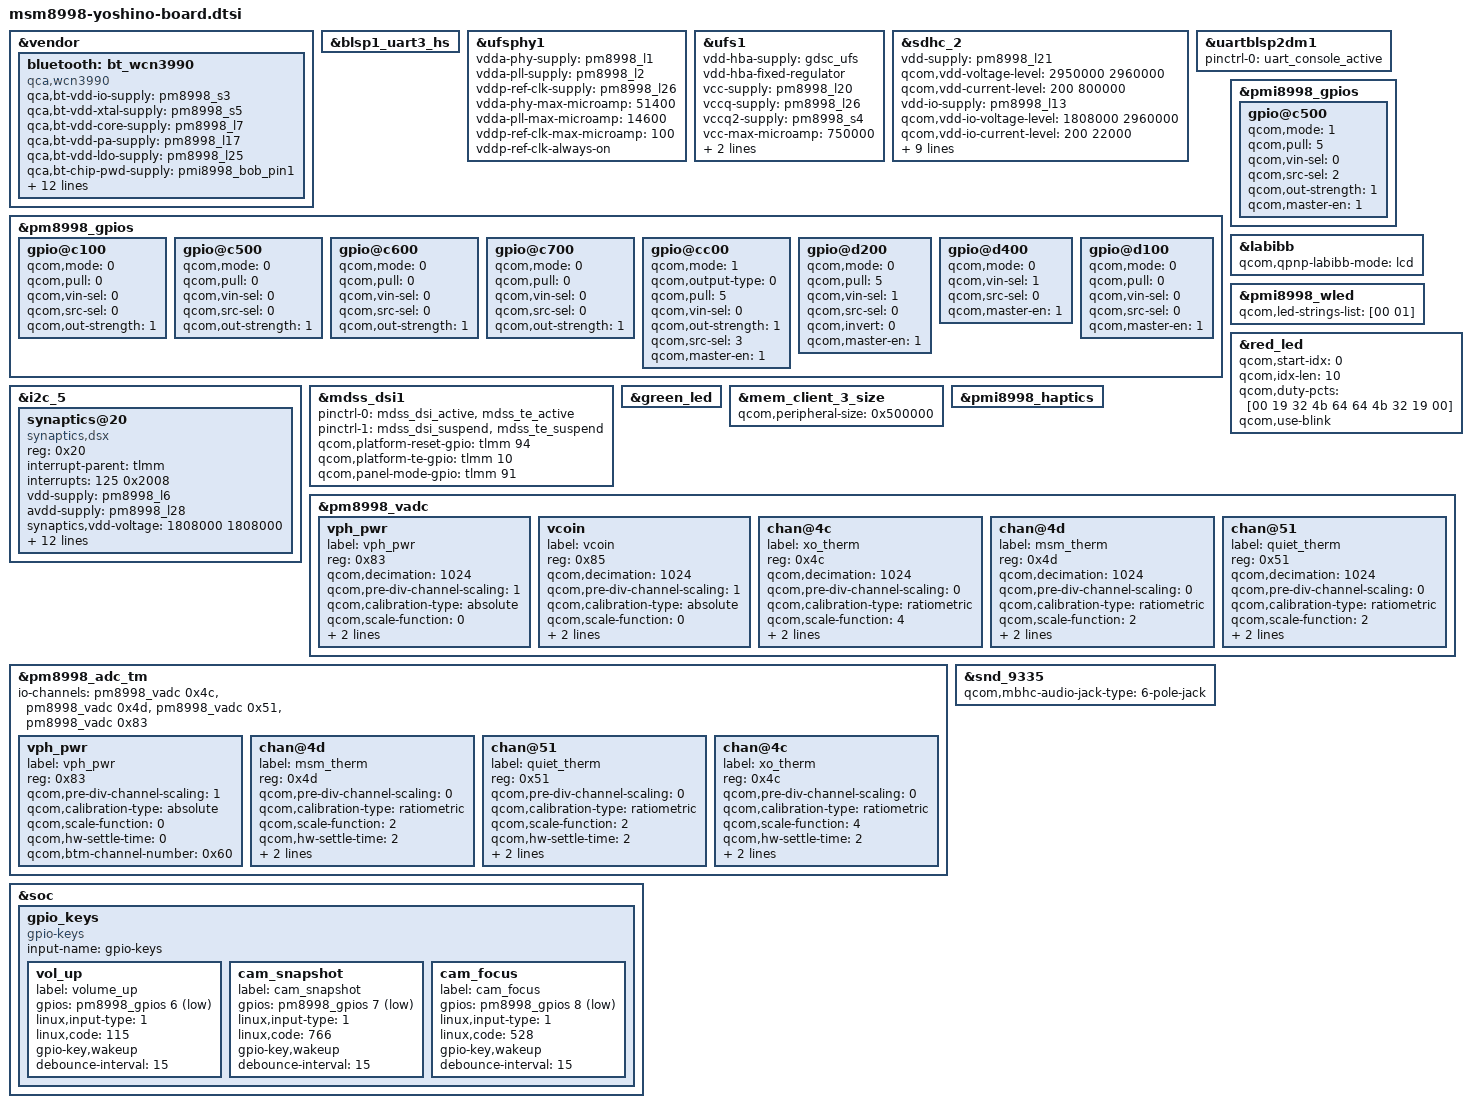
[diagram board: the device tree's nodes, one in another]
/* Copyright (c) 2016-2018, The Linux Foundation. All rights reserved.
 *
 * This program is free software; you can redistribute it and/or modify
 * it under the terms of the GNU General Public License version 2 and
 * only version 2 as published by the Free Software Foundation.
 *
 * This program is distributed in the hope that it will be useful,
 * but WITHOUT ANY WARRANTY; without even the implied warranty of
 * MERCHANTABILITY or FITNESS FOR A PARTICULAR PURPOSE.  See the
 * GNU General Public License for more details.
 */
/*
 * NOTE: This file has been modified by Sony Mobile Communications Inc.
 * Modifications are Copyright (c) 2016 Sony Mobile Communications Inc,
 * and licensed under the license of the file.
 */
/*
 * Yoshino board configuration derived from msm8998-mtp.dtsi.
 * Reference panels, DP, QTI NQ NFC and WiGig overrides are dropped
 * as they are not present on Yoshino.
 */

#include <dt-bindings/interrupt-controller/irq.h>
&vendor {
	bluetooth: bt_wcn3990 {
		compatible = "qca,wcn3990";
		qca,bt-vdd-io-supply = <&pm8998_s3>;
		qca,bt-vdd-xtal-supply = <&pm8998_s5>;
		qca,bt-vdd-core-supply = <&pm8998_l7>;
		qca,bt-vdd-pa-supply = <&pm8998_l17>;
		qca,bt-vdd-ldo-supply = <&pm8998_l25>;
		qca,bt-chip-pwd-supply = <&pmi8998_bob_pin1>;
		clocks = <&clock_rpmcc RPM_SMD_RF_CLK2_PIN>;
		clock-names = "rf_clk2";

		qca,bt-vdd-io-voltage-level = <1352000 1352000>;
		qca,bt-vdd-xtal-voltage-level = <2040000 2040000>;
		qca,bt-vdd-core-voltage-level = <1800000 1800000>;
		qca,bt-vdd-pa-voltage-level = <1304000 1304000>;
		qca,bt-vdd-ldo-voltage-level = <3312000 3312000>;
		qca,bt-chip-pwd-voltage-level = <3600000 3600000>;

		qca,bt-vdd-io-current-level = <1>; /* LPM/PFM */
		qca,bt-vdd-xtal-current-level = <1>; /* LPM/PFM */
		qca,bt-vdd-core-current-level = <1>; /* LPM/PFM */
		qca,bt-vdd-pa-current-level = <1>; /* LPM/PFM */
		qca,bt-vdd-ldo-current-level = <1>; /* LPM/PFM */
	};
};

&blsp1_uart3_hs {
	status = "ok";
};

&ufsphy1 {
	vdda-phy-supply = <&pm8998_l1>;
	vdda-pll-supply = <&pm8998_l2>;
	vddp-ref-clk-supply = <&pm8998_l26>;
	vdda-phy-max-microamp = <51400>;
	vdda-pll-max-microamp = <14600>;
	vddp-ref-clk-max-microamp = <100>;
	vddp-ref-clk-always-on;
	status = "ok";
};

&ufs1 {
	vdd-hba-supply = <&gdsc_ufs>;
	vdd-hba-fixed-regulator;
	vcc-supply = <&pm8998_l20>;
	vccq-supply = <&pm8998_l26>;
	vccq2-supply = <&pm8998_s4>;
	vcc-max-microamp = <750000>;
	vccq-max-microamp = <560000>;
	vccq2-max-microamp = <750000>;
	status = "ok";
};

&sdhc_2 {
	vdd-supply = <&pm8998_l21>;
	qcom,vdd-voltage-level = <2950000 2960000>;
	qcom,vdd-current-level = <200 800000>;

	vdd-io-supply = <&pm8998_l13>;
	qcom,vdd-io-voltage-level = <1808000 2960000>;
	qcom,vdd-io-current-level = <200 22000>;

	pinctrl-names = "active", "sleep";
	pinctrl-0 = <&sdc2_clk_on  &sdc2_cmd_on &sdc2_data_on &sdc2_cd_on>;
	pinctrl-1 = <&sdc2_clk_off &sdc2_cmd_off &sdc2_data_off &sdc2_cd_off>;

	qcom,clk-rates = <400000 20000000 25000000
				50000000 100000000 200000000>;
	qcom,bus-speed-mode = "SDR12", "SDR25", "SDR50", "DDR50", "SDR104";

	cd-gpios = <&tlmm 95 0x1>;

	status = "ok";
};

&uartblsp2dm1 {
	status = "ok";
	pinctrl-names = "default";
	pinctrl-0 = <&uart_console_active>;
};

&pm8998_gpios {
	/* GPIO 2 for Home Key */
	gpio@c100 {
		status = "okay";
		qcom,mode = <0>;
		qcom,pull = <0>;
		qcom,vin-sel = <0>;
		qcom,src-sel = <0>;
		qcom,out-strength = <1>;
	};

	/* GPIO 6 for Vol+ Key */
	gpio@c500 {
		status = "okay";
		qcom,mode = <0>;
		qcom,pull = <0>;
		qcom,vin-sel = <0>;
		qcom,src-sel = <0>;
		qcom,out-strength = <1>;
	};

	/* GPIO 7 for Snapshot Key */
	gpio@c600 {
		status = "okay";
		qcom,mode = <0>;
		qcom,pull = <0>;
		qcom,vin-sel = <0>;
		qcom,src-sel = <0>;
		qcom,out-strength = <1>;
	};

	/* GPIO 8 for Focus Key */
	gpio@c700 {
		status = "okay";
		qcom,mode = <0>;
		qcom,pull = <0>;
		qcom,vin-sel = <0>;
		qcom,src-sel = <0>;
		qcom,out-strength = <1>;
	};

	gpio@cc00 { /* GPIO 13 */
		qcom,mode = <1>;
		qcom,output-type = <0>;
		qcom,pull = <5>;
		qcom,vin-sel = <0>;
		qcom,out-strength = <1>;
		qcom,src-sel = <3>;
		qcom,master-en = <1>;
		status = "okay";
	};

	gpio@d200 { /* GPIO 19 - wil6210 refclk3_en */
		qcom,mode = <0>;		/* Input */
		qcom,pull = <5>;		/* No Pull */
		qcom,vin-sel = <1>;		/* VIN1 GPIO_MV */
		qcom,src-sel = <0>;		/* GPIO */
		qcom,invert = <0>;		/* Invert */
		qcom,master-en = <1>;		/* Enable GPIO */
		status = "okay";
	};

	/* GPIO 21 (NFC_CLK_REQ) */
	gpio@d400 {
		qcom,mode = <0>;
		qcom,vin-sel = <1>;
		qcom,src-sel = <0>;
		qcom,master-en = <1>;
		status = "okay";
	};

	/* GPIO 18 SMB138X */
	gpio@d100 {
		qcom,mode = <0>;
		qcom,pull = <0>;
		qcom,vin-sel = <0>;
		qcom,src-sel = <0>;
		qcom,master-en = <1>;
		status = "okay";
	};
};

&pmi8998_gpios {
	/* GPIO 6 for the internal QNOVO discharge FET control signal */
	gpio@c500 {
		status = "okay";
		qcom,mode = <1>;
		qcom,pull = <5>;
		qcom,vin-sel = <0>;
		qcom,src-sel = <2>;
		qcom,out-strength = <1>;
		qcom,master-en = <1>;
	};
};

&i2c_5 {
	status = "okay";
	synaptics@20 {
		compatible = "synaptics,dsx";
		reg = <0x20>;
		interrupt-parent = <&tlmm>;
		interrupts = <125 0x2008>;
		vdd-supply = <&pm8998_l6>;
		avdd-supply = <&pm8998_l28>;
		synaptics,vdd-voltage = <1808000 1808000>;
		synaptics,avdd-voltage = <3008000 3008000>;
		synaptics,vdd-current = <40000>;
		synaptics,avdd-current = <20000>;
		pinctrl-names = "pmx_ts_active", "pmx_ts_suspend";
		pinctrl-0 = <&ts_active>;
		pinctrl-1 = <&ts_int_suspend &ts_reset_suspend>;
		synaptics,display-coords = <0 0 1439 2559>;
		synaptics,panel-coords = <0 0 1439 2559>;
		synaptics,reset-gpio = <&tlmm 89 0x00>;
		synaptics,irq-gpio = <&tlmm 125 0x2008>;
		synaptics,disable-gpios;
		synaptics,fw-name = "PR1702898-s3528t_60QHD_00400001.img";
	};
};

&mdss_dsi1 {
	pinctrl-names = "mdss_default", "mdss_sleep";
	pinctrl-0 = <&mdss_dsi_active &mdss_te_active>;
	pinctrl-1 = <&mdss_dsi_suspend &mdss_te_suspend>;
	qcom,platform-reset-gpio = <&tlmm 94 0>;
	qcom,platform-te-gpio = <&tlmm 10 0>;
	qcom,panel-mode-gpio = <&tlmm 91 0>;
};

&labibb {
	status = "ok";
	qcom,qpnp-labibb-mode = "lcd";
};

&pmi8998_wled {
	qcom,led-strings-list = [00 01];
};

&red_led {
	/delete-property/ linux,default-trigger;
	qcom,start-idx = <0>;
	qcom,idx-len = <10>;
	qcom,duty-pcts = [00 19 32 4b 64
			64 4b 32 19 00];
	qcom,use-blink;
};

&green_led {
	/delete-property/ linux,default-trigger;
};

&mem_client_3_size {
	qcom,peripheral-size = <0x500000>;
};

&pmi8998_haptics {
	status = "okay";
};

&pm8998_vadc {
	vph_pwr {
		label = "vph_pwr";
		reg = <0x83>;
		qcom,decimation = <1024>;
		qcom,pre-div-channel-scaling = <1>;
		qcom,calibration-type = "absolute";
		qcom,scale-function = <0>;
		qcom,hw-settle-time = <0>;
		qcom,fast-avg-setup = <0>;
	};

	vcoin {
		label = "vcoin";
		reg = <0x85>;
		qcom,decimation = <1024>;
		qcom,pre-div-channel-scaling = <1>;
		qcom,calibration-type = "absolute";
		qcom,scale-function = <0>;
		qcom,hw-settle-time = <0>;
		qcom,fast-avg-setup = <0>;
	};

	chan@4c {
		label = "xo_therm";
		reg = <0x4c>;
		qcom,decimation = <1024>;
		qcom,pre-div-channel-scaling = <0>;
		qcom,calibration-type = "ratiometric";
		qcom,scale-function = <4>;
		qcom,hw-settle-time = <2>;
		qcom,fast-avg-setup = <0>;
	};

	chan@4d {
		label = "msm_therm";
		reg = <0x4d>;
		qcom,decimation = <1024>;
		qcom,pre-div-channel-scaling = <0>;
		qcom,calibration-type = "ratiometric";
		qcom,scale-function = <2>;
		qcom,hw-settle-time = <2>;
		qcom,fast-avg-setup = <0>;
	};

	chan@51 {
		label = "quiet_therm";
		reg = <0x51>;
		qcom,decimation = <1024>;
		qcom,pre-div-channel-scaling = <0>;
		qcom,calibration-type = "ratiometric";
		qcom,scale-function = <2>;
		qcom,hw-settle-time = <2>;
		qcom,fast-avg-setup = <0>;
	};
};

&pm8998_adc_tm {
	io-channels = <&pm8998_vadc 0x4c>,
		      <&pm8998_vadc 0x4d>,
		      <&pm8998_vadc 0x51>,
		      <&pm8998_vadc 0x83>;
	vph_pwr {
		label = "vph_pwr";
		reg = <0x83>;
		qcom,pre-div-channel-scaling = <1>;
		qcom,calibration-type = "absolute";
		qcom,scale-function = <0>;
		qcom,hw-settle-time = <0>;
		qcom,btm-channel-number = <0x60>;
	};

	chan@4d {
		label = "msm_therm";
		reg = <0x4d>;
		qcom,pre-div-channel-scaling = <0>;
		qcom,calibration-type = "ratiometric";
		qcom,scale-function = <2>;
		qcom,hw-settle-time = <2>;
		qcom,btm-channel-number = <0x68>;
		qcom,thermal-node;
	};

	chan@51 {
		label = "quiet_therm";
		reg = <0x51>;
		qcom,pre-div-channel-scaling = <0>;
		qcom,calibration-type = "ratiometric";
		qcom,scale-function = <2>;
		qcom,hw-settle-time = <2>;
		qcom,btm-channel-number = <0x70>;
		qcom,thermal-node;
	};

	chan@4c {
		label = "xo_therm";
		reg = <0x4c>;
		qcom,pre-div-channel-scaling = <0>;
		qcom,calibration-type = "ratiometric";
		qcom,scale-function = <4>;
		qcom,hw-settle-time = <2>;
		qcom,btm-channel-number = <0x78>;
		qcom,thermal-node;
	};
};

&snd_9335 {
	qcom,mbhc-audio-jack-type = "6-pole-jack";
};

&soc {
	gpio_keys {
		compatible = "gpio-keys";
		input-name = "gpio-keys";
		status = "okay";

		vol_up {
			label = "volume_up";
			gpios = <&pm8998_gpios 6 0x1>;
			linux,input-type = <1>;
			linux,code = <115>;
			gpio-key,wakeup;
			debounce-interval = <15>;
		};

		cam_snapshot {
			label = "cam_snapshot";
			gpios = <&pm8998_gpios 7 0x1>;
			linux,input-type = <1>;
			linux,code = <766>;
			gpio-key,wakeup;
			debounce-interval = <15>;
		};

		cam_focus {
			label = "cam_focus";
			gpios = <&pm8998_gpios 8 0x1>;
			linux,input-type = <1>;
			linux,code = <528>;
			gpio-key,wakeup;
			debounce-interval = <15>;
		};
	};
};

/*
&vendor {
	mtp_batterydata: qcom,battery-data {
		qcom,batt-id-range-pct = <15>;
		#include "fg-gen3-batterydata-itech-3000mah.dtsi"
		#include "fg-gen3-batterydata-ascent-3450mah.dtsi"
		#include "fg-gen3-batterydata-demo-6000mah.dtsi"
	};
};

&pmi8998_fg {
	qcom,battery-data = <&mtp_batterydata>;
};
*/
